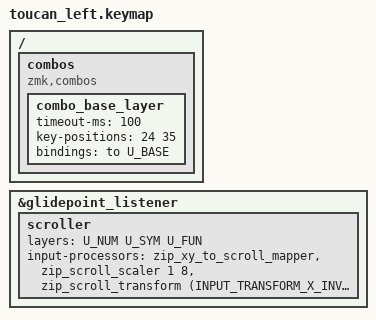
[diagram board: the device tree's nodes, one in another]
// Copyright 2021 Manna Harbour
// https://github.com/manna-harbour/miryoku

#include "../miryoku/custom_config.h"
#include "../miryoku/mapping/42/toucan.h"
#include "../miryoku/miryoku.dtsi"

/ {
    combos {
        compatible = "zmk,combos";
        combo_base_layer {
            timeout-ms = <100>;
            key-positions = <24 35>; // LSHIFT + RSHIFT
            bindings = <&to U_BASE>;
            // layers = <U_TAP U_EXTRA>; // uncomment to restrict to TAP/EXTRA only
        };
    };
};

&glidepoint_listener {
    scroller {
        layers = <U_NUM U_SYM U_FUN>; // right thumb layers (7, 8, 9)
        input-processors = <
            &zip_xy_to_scroll_mapper
            &zip_scroll_scaler 1 8  // less sensitive (was 1 5)
            &zip_scroll_transform (INPUT_TRANSFORM_X_INVERT | INPUT_TRANSFORM_Y_INVERT)
        >;
    };
};
